# MDR1923VK014 register map
Vendor: Milandr; Series: ARMCM0; File version: 2.0
CPU: CM0 r0p0, little endian, no MPU, no FPU, 3 interrupt priority bits
Registers are 32-bit, read-write, reset 0x0 unless marked. A register's access mark holds for its fields unless they carry their own. Offsets are from the block's base; [hi:lo] are bit positions; lines under a group give offsets from that group; {n}, {i} and the like mark numbered series; 'fields as' and 'values as' point back to an identical list.

## MDR_CAN1 — CAN Control
Base 0x40090000
Same registers: MDR_CAN2 0x40091000
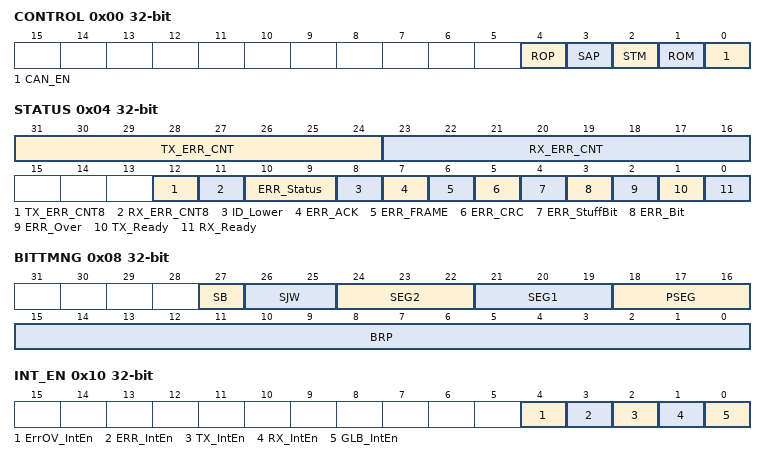
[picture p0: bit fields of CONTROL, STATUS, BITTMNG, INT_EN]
0x00 CONTROL
  [all] fields
    0=Off (Disabled); 1=On (Enabled)
  [4] ROP — Receive Own Packets
  [3] SAP — Send Ack for Own Packets
  [2] STM — Self Test Mode
  [1] ROM — Read Only Mode
  [0] CAN_EN — Enable CAN
0x04 STATUS
  [31:24] TX_ERR_CNT — Tx Error Counter
  [23:16] RX_ERR_CNT — Rx Error Counter
  [12] TX_ERR_CNT8 — TEC > 255, BusOff
    0=Off (Event Inactive); 1=On (Event Active)
  [11] RX_ERR_CNT8 — REC > 255, BusOff
    0=Off (Event Inactive); 1=On (Event Active)
  [10:9] ERR_Status — Eror status
    0=Active mode; 1=Passive (Pasiive error mode); 2=BusOff (Bus Disable)
  [8] ID_Lower — Arbitrage failure
    0=Off (Event Inactive); 1=On (Event Active)
  [7] ERR_ACK — Acknowledge error
    0=Off (Event Inactive); 1=On (Event Active)
  [6] ERR_FRAME — Wrong Frame structure
    0=Off (Event Inactive); 1=On (Event Active)
  [5] ERR_CRC — CRC Error
    0=Off (Event Inactive); 1=On (Event Active)
  [4] ERR_StuffBit — Error in Staff Bit
    0=Off (Event Inactive); 1=On (Event Active)
  [3] ERR_Bit — Error while TX some bit
    0=Off (Event Inactive); 1=On (Event Active)
  [2] ERR_Over — TEC o REC exceeds ERROR_MAX
    0=Off (Event Inactive); 1=On (Event Active)
  [1] TX_Ready — Some buff has data to send
    0=Off (Event Inactive); 1=On (Event Active)
  [0] RX_Ready — Some Buff Data received
    0=Off (Event Inactive); 1=On (Event Active)
0x08 BITTMNG — Bit Timing register
  [27] SB — Line Sampling Count
    0=Single sampling; 1=Triple sampling
  [26:25] SJW — Sync phase deviation
    {v}={v+1}TQ (Delay) (v=0..3)
  [24:22] SEG2 — Delay after line sampling
    {v}={v+1}TQ (Delay) (v=0..7)
  [21:19] SEG1 — Delay before line sampling
    {v}={v+1}TQ (Delay) (v=0..7)
  [18:16] PSEG — Propagation time in TQ
    {v}={v+1}TQ (Delay) (v=0..7)
  [15:0] BRP — Boud Rate Prescaler to TQ
0x10 INT_EN — IRQ Enable
  [all] fields
    0=Disabled (Disable IRQ); 1=Enabled (Enable IRQ)
  [4] ErrOV_IntEn — Enable IRQ of Error Over
  [3] ERR_IntEn — Enable IRQ on Error
  [2] TX_IntEn — Enable IRQ on TX
  [1] RX_IntEn — Enable IRQ on RX
  [0] GLB_IntEn — IRQ Enable Global
0x1C OVER — ERROR_MAX level
  [7:0] ERROR_MAX — Level of TEC or REC errors to OverIRQ
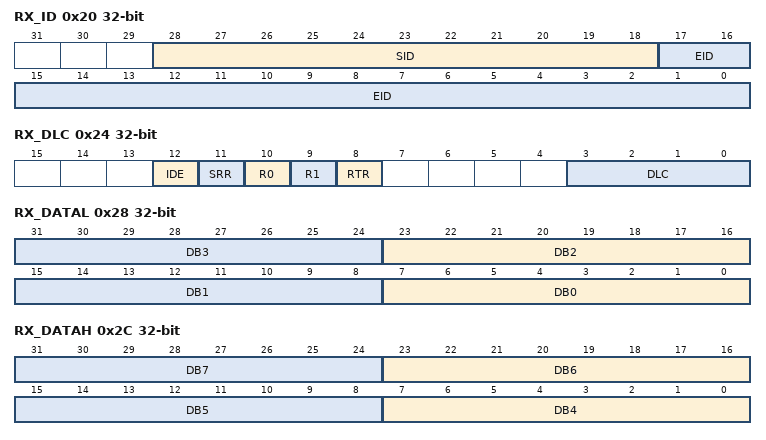
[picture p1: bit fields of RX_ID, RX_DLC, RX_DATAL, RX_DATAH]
0x20 RX_ID (reset mask 0xFFFFFFF) — Last Received ID
  [28:18] SID — Standard frame ID
  [17:0] EID — Extended frame ID
0x24 RX_DLC — Last Received ControlField
  [12] IDE — Frame format
    0=Standard frame; 1=Extended frame
  [11] SRR — Substitute Remote Request
    0=Off (Disabled); 1=On (Enabled)
  [10] R0 — Reserved bit R0
    0=Off (Disabled); 1=On (Enabled)
  [9] R1 — Reserved bit R1
    0=Off (Disabled); 1=On (Enabled)
  [8] RTR — Remote transmission Request
    0=Off (Disabled); 1=On (Enabled)
  [3:0] DLC — Data Length Code
    0=NoData (Normal Operation); {v}=Bytes_{v} (Byte Count) (v=1..8)
0x28 RX_DATAL — Received Byte[0]..Byte[3]
  [8n+7:8n] DB{n} (n=0..3) — Byte {n}
0x2C RX_DATAH — Received Byte[4]..Byte[7]
  [8n-25:8n-32] DB{n} (n=4..7) — Byte {n-4}
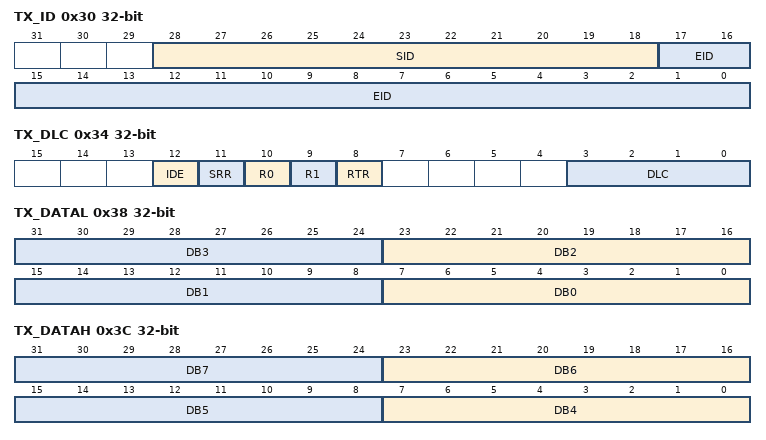
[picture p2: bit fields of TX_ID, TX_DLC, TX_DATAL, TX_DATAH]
0x30 TX_ID (reset mask 0xFFFFFFF) — Last Sent ID
  [28:18] SID — Standard frame ID
  [17:0] EID — Extended frame ID
0x34 TX_DLC — Last Sent ControlField
  fields as RX_DLC
0x38 TX_DATAL — Last Sent Byte[4]..Byte[7]
  [8n+7:8n] DB{n} (n=0..3) — Byte {n}
0x3C TX_DATAH — Last Sent Byte[4]..Byte[7]
  [8n-25:8n-32] DB{n} (n=4..7) — Byte {n-4}
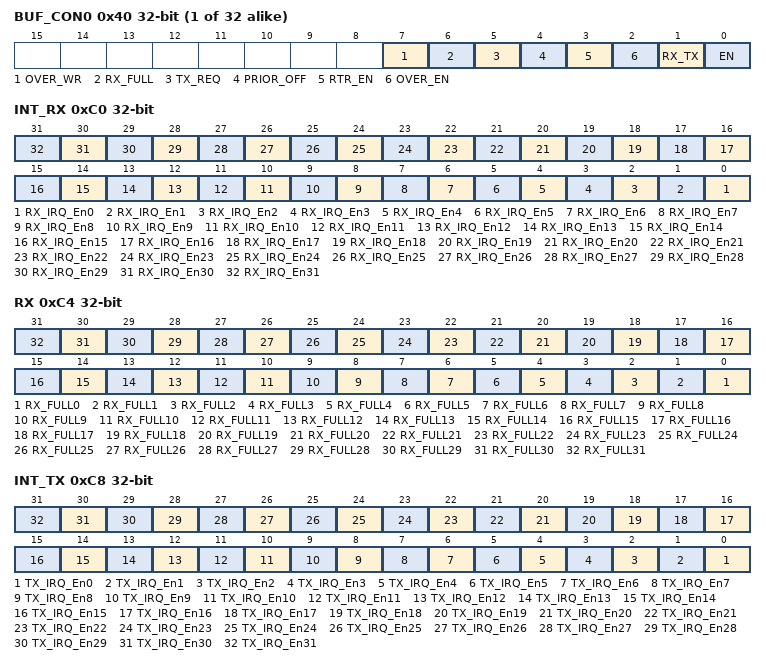
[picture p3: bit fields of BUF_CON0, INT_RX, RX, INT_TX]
{0x40+4i} BUF_CON{i} (i=0..31) — Buffer control
  [7] OVER_WR — Data overwritten
    0=Off (Disabled); 1=On (Enabled)
  [6] RX_FULL — Has new data
    0=Off (Disabled); 1=On (Enabled)
  [5] TX_REQ — Request to send
    0=Off (Disabled); 1=On (Enabled)
  [4] PRIOR_OFF — Send priority Off
    0=Off (Disabled); 1=On (Enabled)
  [3] RTR_EN — RTR ACK enable
    0=Off (Disabled); 1=On (Enabled)
  [2] OVER_EN — Overwrite enable
    0=Off (Disabled); 1=On (Enabled)
  [1] RX_TX — Buffer Direction
    0=TX (Output buffer); 1=RX (Input buffer)
  [0] EN — Buffer enable
    0=Off (Disabled); 1=On (Enabled)
0xC0 INT_RX — Enable Buffs' RX IRQ
  [n] RX_IRQ_En{n} (n=0..31)
    0=Off (IRQ Disabled); 1=On (IRQ Enabled)
0xC4 RX — Buffs' RX_FIFO Full
  [n] RX_FULL{n} (n=0..31)
    0=Empty (No Data); 1=Full (Has Data)
0xC8 INT_TX — Enable Buffs' TX IRQ
  [n] TX_IRQ_En{n} (n=0..31)
    0=Off (IRQ Disabled); 1=On (IRQ Enabled)
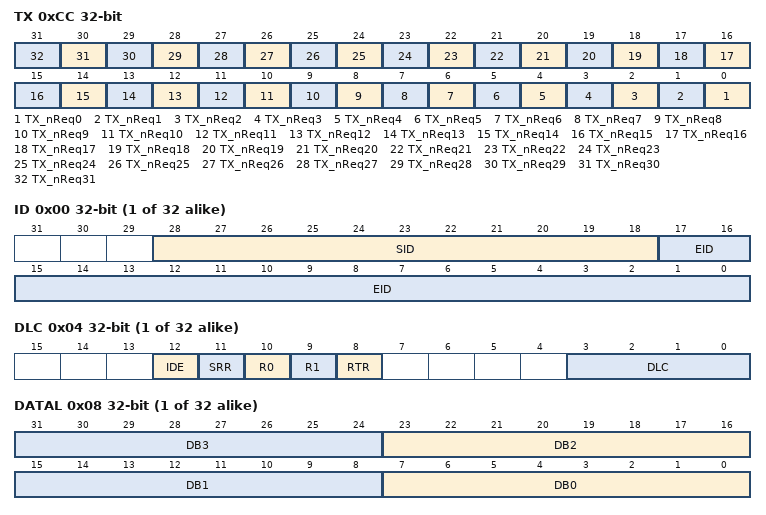
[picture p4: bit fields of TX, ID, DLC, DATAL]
0xCC TX — TX_nReq buffs' state
  [n] TX_nReq{n} (n=0..31)
    0=Active (Tx_Req is active); 1=Off (No req)
{0x200+0x10*i} BUF{i} (i=0..31) group — TX or RX buffer control
  0x00 ID (reset mask 0xFFFFFFF) — packet ID
    [28:18] SID — Standard frame ID
    [17:0] EID — Extended frame ID
  0x04 DLC — ControlField
    fields as RX_DLC
  0x08 DATAL — Byte[4]..Byte[7]
    [8n+7:8n] DB{n} (n=0..3) — Byte {n}
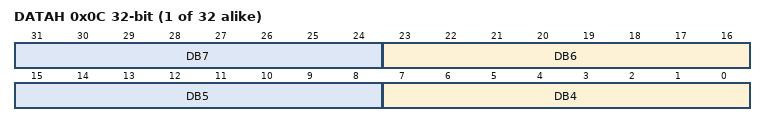
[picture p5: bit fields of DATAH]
  0x0C DATAH — [4]..Byte[7]
    [8n-25:8n-32] DB{n} (n=4..7) — Byte {n-4}
{0x500+8i} FILTER{i} (i=0..31) group — Buffer Receive Filters
  0x00 MASK — MASK for receiver ID
  0x04 FILTER — FILTER for receiver ID
